AUTOSAR XML (schema 00044)
package /E40_Platform_System_SystemPackage/Components
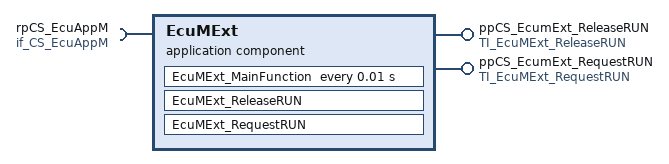
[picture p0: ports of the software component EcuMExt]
  application sw component type EcuMExt
    provide port ppCS_EcumExt_ReleaseRUN: server-com-spec{operation=ReleaseRUN, queue-length=1}, provided-interface=TI_EcuMExt_ReleaseRUN
    provide port ppCS_EcumExt_RequestRUN: server-com-spec{operation=RequestRUN, queue-length=1}, provided-interface=TI_EcuMExt_RequestRUN
    require port rpCS_EcuAppM: required-com-specs=[EcuAppM_SetWakeupSources, Init], required-interface=if_CS_EcuAppM
    behavior IB_EcuMExt
      timing event TEEcuMExt_MainFunction: start-on-event=EcuMExt_MainFunction, period=0.01
      operation invoked event OIE_ppCS_EcumExt_ReleaseRUN_EcuMExt_ReleaseRUNTrigByReleaseRUN: start-on-event=EcuMExt_ReleaseRUN, operation=ppCS_EcumExt_ReleaseRUN.ReleaseRUN
      operation invoked event OIE_ppCS_EcumExt_RequestRUN_EcuMExt_RequestRUNTrigByRequestRUN: start-on-event=EcuMExt_RequestRUN, operation=ppCS_EcumExt_RequestRUN.RequestRUN
      port-api-options:
        enable-take-address=false, indirect-api=false, port=ppCS_EcumExt_ReleaseRUN
        enable-take-address=false, indirect-api=false, port=ppCS_EcumExt_RequestRUN
        enable-take-address=false, indirect-api=false, port=rpCS_EcuAppM
      runnable EcuMExt_MainFunction: can-be-invoked-concurrently=true
        sync call OA_rpCS_EcuAppM_Init: operation=rpCS_EcuAppM.Init
        sync call OA_rpCS_EcuAppM_EcuAppM_SetWakeupSources: operation=rpCS_EcuAppM.EcuAppM_SetWakeupSources
      runnable EcuMExt_ReleaseRUN: can-be-invoked-concurrently=true
        sync call OA_rpCS_EcuAppM_Init: operation=rpCS_EcuAppM.Init
        sync call OA_rpCS_EcuAppM_EcuAppM_SetWakeupSources: operation=rpCS_EcuAppM.EcuAppM_SetWakeupSources
      runnable EcuMExt_RequestRUN: can-be-invoked-concurrently=true
        sync call OA_rpCS_EcuAppM_Init: operation=rpCS_EcuAppM.Init
        sync call OA_rpCS_EcuAppM_EcuAppM_SetWakeupSources: operation=rpCS_EcuAppM.EcuAppM_SetWakeupSources
  swc implementation IMPL_EcuMExt: behavior=IB_EcuMExt
